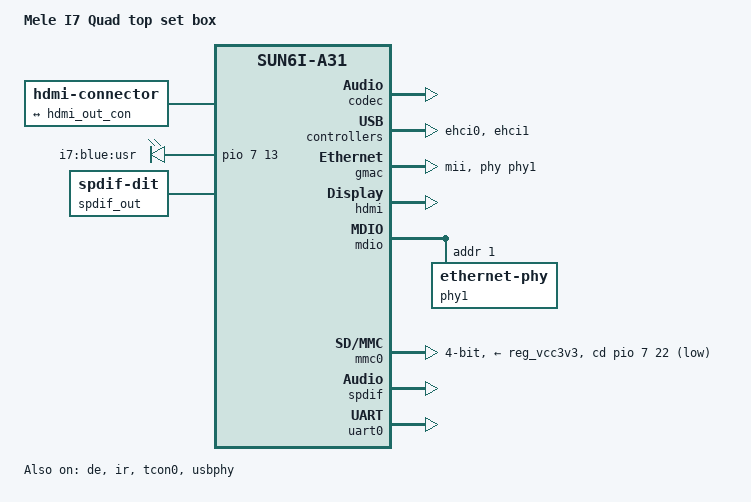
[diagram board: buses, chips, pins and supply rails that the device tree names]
/dts-v1/;
#include "sun6i-a31.dtsi"
#include "sunxi-common-regulators.dtsi"
#include <dt-bindings/gpio/gpio.h>
/ {
	model = "Mele I7 Quad top set box";
	compatible = "mele,i7", "allwinner,sun6i-a31";
	aliases {
		serial0 = &uart0;
	};
	chosen {
		stdout-path = "serial0:115200n8";
	};
	hdmi-connector {
		compatible = "hdmi-connector";
		type = "a";
		port {
			hdmi_con_in: endpoint {
				remote-endpoint = <&hdmi_out_con>;
			};
		};
	};
	leds {
		compatible = "gpio-leds";
		led {
			label = "i7:blue:usr";
			gpios = <&pio 7 13 GPIO_ACTIVE_HIGH>;
		};
	};
	sound {
		compatible = "simple-audio-card";
		simple-audio-card,name = "On-board SPDIF";
		simple-audio-card,cpu {
			sound-dai = <&spdif>;
		};
		simple-audio-card,codec {
			sound-dai = <&spdif_out>;
		};
	};
	spdif_out: spdif-out {
		#sound-dai-cells = <0>;
		compatible = "linux,spdif-dit";
	};
};
&codec {
	allwinner,audio-routing =
		"Headphone", "HP";
	status = "okay";
};
&de {
	status = "okay";
};
&ehci0 {
	status = "okay";
};
&ehci1 {
	status = "okay";
};
&gmac {
	pinctrl-names = "default";
	pinctrl-0 = <&gmac_mii_pins>;
	phy-handle = <&phy1>;
	phy-mode = "mii";
	status = "okay";
};
&hdmi {
	status = "okay";
};
&hdmi_out {
	hdmi_out_con: endpoint {
		remote-endpoint = <&hdmi_con_in>;
	};
};
&ir {
	pinctrl-names = "default";
	pinctrl-0 = <&s_ir_rx_pin>;
	status = "okay";
};
&mdio {
	phy1: ethernet-phy@1 {
		reg = <1>;
	};
};
&mmc0 {
	vmmc-supply = <&reg_vcc3v3>;
	bus-width = <4>;
	cd-gpios = <&pio 7 22 GPIO_ACTIVE_LOW>;  
	status = "okay";
};
&reg_usb1_vbus {
	gpio = <&pio 2 27 GPIO_ACTIVE_HIGH>;
	status = "okay";
};
&spdif {
	pinctrl-names = "default";
	pinctrl-0 = <&spdif_tx_pin>;
	status = "okay";
};
&tcon0 {
	status = "okay";
};
&uart0 {
	pinctrl-names = "default";
	pinctrl-0 = <&uart0_ph_pins>;
	status = "okay";
};
&usbphy {
	usb1_vbus-supply = <&reg_usb1_vbus>;
	status = "okay";
};
